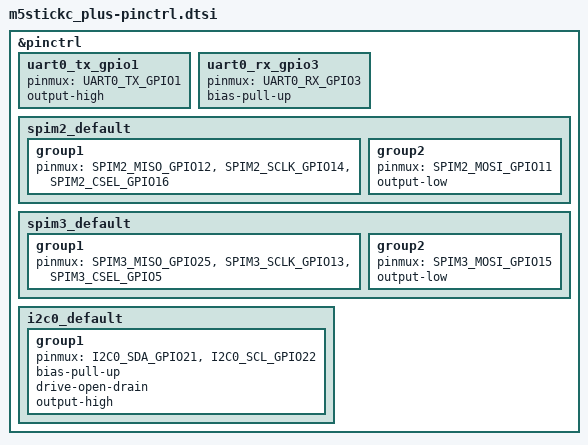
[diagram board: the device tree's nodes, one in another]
/*
 * Copyright (c) 2022 AVSystem Sławomir Wolf Sp.j. (AVSystem)
 *
 * SPDX-License-Identifier: Apache-2.0
 */

#include <zephyr/dt-bindings/pinctrl/esp-pinctrl-common.h>
#include <dt-bindings/pinctrl/esp32-pinctrl.h>
#include <zephyr/dt-bindings/pinctrl/esp32-gpio-sigmap.h>

&pinctrl {

	uart0_tx_gpio1: uart0_tx_gpio1 {
		pinmux = <UART0_TX_GPIO1>;
		output-high;
	};

	uart0_rx_gpio3: uart0_rx_gpio3 {
		pinmux = <UART0_RX_GPIO3>;
		bias-pull-up;
	};

	spim2_default: spim2_default {
		group1 {
			pinmux = <SPIM2_MISO_GPIO12>,
				 <SPIM2_SCLK_GPIO14>,
				 <SPIM2_CSEL_GPIO16>;
		};
		group2 {
			pinmux = <SPIM2_MOSI_GPIO11>;
			output-low;
		};
	};

	spim3_default: spim3_default {
		group1 {
			pinmux = <SPIM3_MISO_GPIO25>,
				 <SPIM3_SCLK_GPIO13>,
				 <SPIM3_CSEL_GPIO5>;
		};
		group2 {
			pinmux = <SPIM3_MOSI_GPIO15>;
			output-low;
		};
	};

	i2c0_default: i2c0_default {
		group1 {
			pinmux = <I2C0_SDA_GPIO21>,
				 <I2C0_SCL_GPIO22>;
			bias-pull-up;
			drive-open-drain;
			output-high;
		};
	};
};
